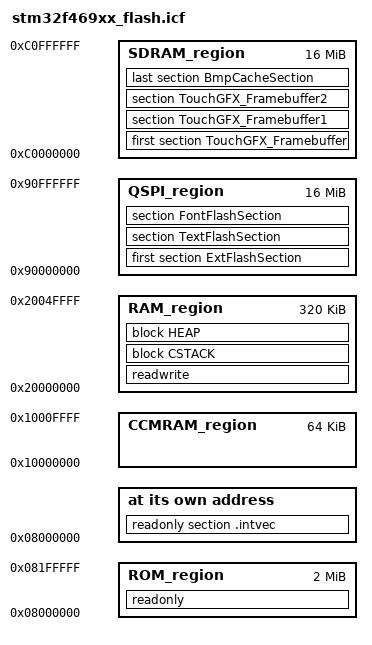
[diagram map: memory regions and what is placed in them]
/*###ICF### Section handled by ICF editor, don't touch! ****/
/*-Editor annotation file-*/
/* IcfEditorFile="$TOOLKIT_DIR$\config\ide\IcfEditor\cortex_v1_0.xml" */
/*-Specials-*/
define symbol __ICFEDIT_intvec_start__ = 0x08000000;
/*-Memory Regions-*/
define symbol __ICFEDIT_region_ROM_start__    = 0x08000000;
define symbol __ICFEDIT_region_ROM_end__      = 0x081FFFFF;
define symbol __ICFEDIT_region_RAM_start__    = 0x20000000;
define symbol __ICFEDIT_region_RAM_end__      = 0x2004FFFF;
define symbol __ICFEDIT_region_CCMRAM_start__ = 0x10000000;
define symbol __ICFEDIT_region_CCMRAM_end__   = 0x1000FFFF;
/*-Sizes-*/
define symbol __ICFEDIT_size_cstack__ = 0x1000;
define symbol __ICFEDIT_size_heap__ = 0x1000;
/**** End of ICF editor section. ###ICF###*/

/*-External RAM Memory Regions-*/
define symbol __ICFEDIT_region_SDRAM_start__  = 0xC0000000; /*  16 Mbytes */
define symbol __ICFEDIT_region_SDRAM_end__    = 0xC0FFFFFF;

/*-Quad-SPI Memory Regions-*/
define symbol __ICFEDIT_region_QSPI_start__   = 0x90000000;
define symbol __ICFEDIT_region_QSPI_end__     = 0x90FFFFFF; /*  16 Mbytes */

define memory mem with size = 4G;
define region ROM_region      = mem:[from __ICFEDIT_region_ROM_start__   to __ICFEDIT_region_ROM_end__];
define region RAM_region      = mem:[from __ICFEDIT_region_RAM_start__   to __ICFEDIT_region_RAM_end__];
define region CCMRAM_region   = mem:[from __ICFEDIT_region_CCMRAM_start__ to __ICFEDIT_region_CCMRAM_end__];
define region SDRAM_region    = mem:[from __ICFEDIT_region_SDRAM_start__ to __ICFEDIT_region_SDRAM_end__];
define region QSPI_region     = mem:[from __ICFEDIT_region_QSPI_start__  to __ICFEDIT_region_QSPI_end__];

define block CSTACK    with alignment = 8, size = __ICFEDIT_size_cstack__   { };
define block HEAP      with alignment = 8, size = __ICFEDIT_size_heap__     { };

initialize by copy { readwrite };
do not initialize  { section .noinit, section TouchGFX_Framebuffer, section TouchGFX_Framebuffer1, section TouchGFX_Framebuffer2, section BmpCacheSection };

place at address mem:__ICFEDIT_intvec_start__ { readonly section .intvec };

place in ROM_region   { readonly };
place in RAM_region   { readwrite,
                        block CSTACK, block HEAP };
place in SDRAM_region { first section TouchGFX_Framebuffer, section TouchGFX_Framebuffer1, section TouchGFX_Framebuffer2, last section BmpCacheSection };
place in QSPI_region  { first section ExtFlashSection
                      , section TextFlashSection
                      , section FontFlashSection };
